AUTOSAR XML (schema 00049)
package /ISOFT/PlatformComponents/sm/swc
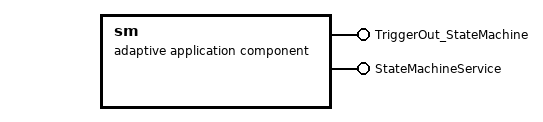
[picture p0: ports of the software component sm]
  adaptive application sw component type sm
    provide port TriggerOut_StateMachine: provided-interface=TriggerOut_StateMachine
    provide port StateMachineService: provided-interface=StateMachineService
